# DA_IP_ADC_3v16bSAR_NN_C90LP: IP-XACT component
VLNV Origen:Origen:DA_IP_ADC_3v16bSAR_NN_C90LP:1.7

## Address spaces and blocks
.: base 0x0, range 124, width 32

## Registers
Registers are 32-bit, read-write, reset 0x0 unless marked. A register's access mark holds for its fields unless they carry their own. Offsets are from the block's base; lines under a group give offsets from that group; [hi:lo] are bit positions; {n}, {i} and the like mark numbered series; 'fields as' and 'values as' point back to an identical list; <NAME> marks a mode.

## block0
Base 0x00000000
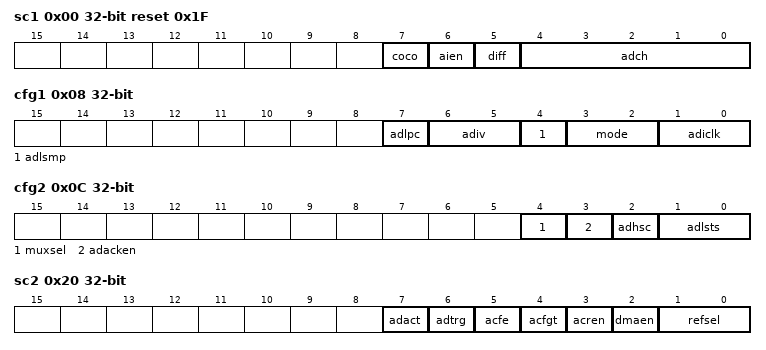
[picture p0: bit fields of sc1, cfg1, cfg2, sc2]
0x00 sc1 reset 0x1F — ADC Status and Control Registers 1
  [7] coco ro — Conversion Complete Flag
    0=Conversion is not completed; 1=Conversion is completed
  [6] aien — Interrupt Enable
    0=Conversion complete interrupt is disabled; 1=Conversion complete interrupt is enabled
  [5] diff — Differential Mode Enable
    0=Single-ended conversions and input channels are selected; 1=Differential conversions and input channels are selected
  [4:0] adch — Input channel select
    0=When DIFF=0, DADP0 is selected as input; when DIFF=1, DAD0 is selected as input. AD0 is selected as input.; 1=When DIFF=0, DADP1 is selected as input; when DIFF=1, DAD1 is selected as input. AD1 is selected as input.; 10=When DIFF=0, DADP2 is selected as input; when DIFF=1, DAD2 is selected as input. AD2 is selected as input.; 11=When DIFF=0, DADP3 is selected as input; when DIFF=1, DAD3 is selected as input. AD3 is selected as input.; 100=When DIFF=0, AD4 is selected as input; when DIFF=1, it is reserved; 101=When DIFF=0, AD5 is selected as input; when DIFF=1, it is reserved; 110=When DIFF=0, AD6 is selected as input; when DIFF=1, it is reserved; 111=When DIFF=0, AD7 is selected as input; when DIFF=1, it is reserved; 0x3E8=When DIFF=0, AD8 is selected as input; when DIFF=1, it is reserved; 0x3E9=When DIFF=0, AD9 is selected as input; when DIFF=1, it is reserved; 0x3F2=When DIFF=0, AD10 is selected as input; when DIFF=1, it is reserved; 0x3F3=When DIFF=0, AD11 is selected as input; when DIFF=1, it is reserved; 0x44C=When DIFF=0, AD12 is selected as input; when DIFF=1, it is reserved; 0x44D=When DIFF=0, AD13 is selected as input; when DIFF=1, it is reserved; 0x456=When DIFF=0, AD14 is selected as input; when DIFF=1, it is reserved; 0x457=When DIFF=0, AD15 is selected as input; when DIFF=1, it is reserved; 0x2710=When DIFF=0, AD16 is selected as input; when DIFF=1, it is reserved; 0x2711=When DIFF=0, AD17 is selected as input; when DIFF=1, it is reserved; 0x271A=When DIFF=0, AD18 is selected as input; when DIFF=1, it is reserved; 0x271B=When DIFF=0, AD19 is selected as input; when DIFF=1, it is reserved; 0x2774=When DIFF=0, AD20 is selected as input; when DIFF=1, it is reserved; 0x2775=When DIFF=0, AD21 is selected as input; when DIFF=1, it is reserved; 0x277E=When DIFF=0, AD22 is selected as input; when DIFF=1, it is reserved; 0x277F=When DIFF=0, AD23 is selected as input; when DIFF=1, it is reserved; 0x2B02=When DIFF=0, Temp Sensor (single-ended) is selected as input; when DIFF=1, Temp Sensor (differential) is selected as input; 0x2B03=When DIFF=0, Bandgap VREF\_OUT (single-ended) is selected as input; when DIFF=1, Bandgap VREF\_OUT (differential) is selected as input; 0x2B5D=When DIFF=0,VREFSH is selected as input; when DIFF=1, -VREFSH (differential) is selected as input. Voltage reference selected is determined by SC2\[REFSEL\].; 0x2B66=When DIFF=0,VREFSL is selected as input; when DIFF=1, it is reserved. Voltage reference selected is determined by SC2\[REFSEL\].; 0x2B67=Module is disabled
0x08 cfg1 — ADC Configuration Register 1
  [7] adlpc — Low-Power Configuration
    0=Normal power configuration; 1=Low-power configuration. The power is reduced at the expense of maximum clock speed.
  [6:5] adiv — Clock Divide Select
    0=The divide ratio is 1 and the clock rate is input clock; 1=The divide ratio is 2 and the clock rate is (input clock)/2; 10=The divide ratio is 4 and the clock rate is (input clock)/4; 11=The divide ratio is 8 and the clock rate is (input clock)/8
  [4] adlsmp — Sample Time Configuration
    0=Short sample time; 1=Long sample time
  [3:2] mode — Conversion mode selection
    0=When DIFF=0:It is single-ended 8-bit conversion; when DIFF=1, it is differential 9-bit conversion with 2\'s complement output; 1=When DIFF=0:It is single-ended 12-bit conversion ; when DIFF=1, it is differential 13-bit conversion with 2\'s complement output; 10=When DIFF=0:It is single-ended 10-bit conversion. ; when DIFF=1, it is differential 11-bit conversion with 2\'s complement output; 11=When DIFF=0:It is single-ended 16-bit conversion..; when DIFF=1, it is differential 16-bit conversion with 2\'s complement output Reserved. Do not set the field to this value.
  [1:0] adiclk — Input Clock Select
    0=Bus clock; 1=Alternate clock 2 (ALTCLK2) Bus clock divided by 2(BUSCLK/2); 10=Alternate clock (ALTCLK); 11=Asynchronous clock (ADACK)
0x0C cfg2 — ADC Configuration Register 2
  [4] muxsel — ADC Mux Select
    0=ADxxa channels are selected; 1=ADxxb channels are selected
  [3] adacken — Asynchronous Clock Output Enable
    0=Asynchronous clock output disabled; Asynchronous clock is enabled only if selected by ADICLK and a conversion is active; 1=Asynchronous clock and clock output is enabled regardless of the state of the ADC
  [2] adhsc — High-Speed Configuration
    0=Normal conversion sequence selected; 1=High-speed conversion sequence selected with 2 additional ADCK cycles to total conversion time
  [1:0] adlsts — Long Sample Time Select
    0=Default longest sample time; 20 extra ADCK cycles; 24 ADCK cycles total; 1=12 extra ADCK cycles; 16 ADCK cycles total sample time; 10=6 extra ADCK cycles; 10 ADCK cycles total sample time; 11=2 extra ADCK cycles; 6 ADCK cycles total sample time
0x10 r ro — ADC Data Result Register
  [15:0] d — Data result
0x18 cv — Compare Value Registers
  [15:0] cv — Compare Value.
0x20 sc2 — Status and Control Register 2
  [7] adact ro — Conversion Active
    0=Conversion not in progress; 1=Conversion in progress
  [6] adtrg — Conversion Trigger Select
    0=Software trigger selected; 1=Hardware trigger selected
  [5] acfe — Compare Function Enable
    0=Compare function disabled; 1=Compare function enabled
  [4] acfgt — Compare Function Greater Than Enable
    0=Configures less than threshold, outside range not inclusive and inside range not inclusive; functionality based on the values placed in CV1 and CV2; 1=Configures greater than or equal to threshold, outside and inside ranges inclusive; functionality based on the values placed in CV1 and CV2
  [3] acren — Compare Function Range Enable
    0=Range function disabled. Only CV1 is compared. \{27}; 1=Range function enabled. Both CV1 and CV2 are compared. \{27}
  [2] dmaen — DMA Enable
    0=DMA is disabled; 1=DMA is enabled and will assert the ADC DMA request during an ADC conversion complete event noted when any of the SC1n\[COCO\] flags is asserted
  [1:0] refsel — Voltage Reference Selection
    0=Default voltage reference pin pair, that is, external pins VREFH and VREFL; 1=Alternate reference pair, that is, VALTH and VALTL . This pair may be additional external pins or internal sources depending on the MCU configuration. See the chip configuration information for details specific to this MCU; 10=Internal bandgap reference and associated ground reference (V BGH and V BGL ). Consult the Chip Configuration information for details specific to this MCU. Reserved; 11=Reserved - Selects default voltage reference (V REFH and V REFL ) pin pair
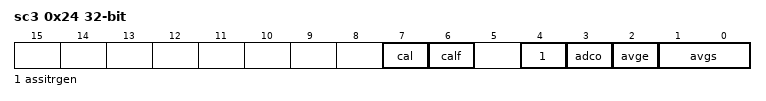
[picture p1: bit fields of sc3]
0x24 sc3 — Status and Control Register 3
  [7] cal — Calibration
  [6] calf — Calibration Failed Flag
    0=Calibration completed normally; 1=Calibration failed. ADC accuracy specifications are not guaranteed.
  [4] assitrgen — Assist Trigger Enable
    0=Writes to ADCSC1 COCO bit don\'t have an affect on ADTRG; 1=Writes to ADCSC1 COCO bit will be reflected into ADTRG register. Note: When ASSITRGEN is set, writes to ADCSC1 are delayed by 1/2 bus cycle to allow ADCSC1 COCO write to be updated in ADTRG register so conversion type can be correctly generated (software if coco write is 1\'b0 causing ADTRG to clear or hardware type if coco write is 1\'b1.). Note: User must ensure no hardware trigger is generated between the time ADCSC1 COCO bit is written if value of ADTRG will change to guarantee correct conversion type is generated.
  [3] adco — Continuous Conversion Enable
    0=One conversion or one set of conversions if the hardware average function is enabled, that is, AVGE=1, after initiating a conversion; 1=Continuous conversions or sets of conversions if the hardware average function is enabled, that is, AVGE=1, after initiating a conversion
  [2] avge — Hardware Average Enable
    0=Hardware average function disabled; 1=Hardware average function enabled
  [1:0] avgs — Hardware Average Select
    0=4 samples averaged; 1=8 samples averaged; 10=16 samples averaged; 11=32 samples averaged
0x28 ofs reset 0x4 — ADC Offset Correction Register
  [15:0] ofs — Offset Error Correction Value
0x2C pg reset 0x8200 — ADC Plus-Side Gain Register
  [15:0] pg — Plus-Side Gain
0x30 mg reset 0x8200 — ADC Minus-Side Gain Register
  [15:0] mg — Minus-Side Gain
0x34 clpd reset 0xA — ADC Plus-Side General Calibration Value Register
  [5:0] clpd — Calibration Value
0x38 clps reset 0x20 — ADC Plus-Side General Calibration Value Register
  [5:0] clps — Calibration Value
0x3C clp4 reset 0x200 — ADC Plus-Side General Calibration Value Register
  [9:0] clp4 — Calibration Value
0x40 clp3 reset 0x100 — ADC Plus-Side General Calibration Value Register
  [8:0] clp3 — Calibration Value
0x44 clp2 reset 0x80 — ADC Plus-Side General Calibration Value Register
  [7:0] clp2 — Calibration Value
0x48 clp1 reset 0x40 — ADC Plus-Side General Calibration Value Register
  [6:0] clp1 — Calibration Value
0x4C clp0 reset 0x20 — ADC Plus-Side General Calibration Value Register
  [5:0] clp0 — Calibration Value
0x54 clmd reset 0xA — ADC Minus-Side General Calibration Value Register
  [5:0] clmd — Calibration Value
0x58 clms reset 0x20 — ADC Minus-Side General Calibration Value Register
  [5:0] clms — Calibration Value
0x5C clm4 reset 0x200 — ADC Minus-Side General Calibration Value Register
  [9:0] clm4 — Calibration Value
0x60 clm3 reset 0x100 — ADC Minus-Side General Calibration Value Register
  [8:0] clm3 — Calibration Value
0x64 clm2 reset 0x80 — ADC Minus-Side General Calibration Value Register
  [7:0] clm2 — Calibration Value
0x68 clm1 reset 0x40 — ADC Minus-Side General Calibration Value Register
  [6:0] clm1 — Calibration Value
0x6C clm0 reset 0x20 — ADC Minus-Side General Calibration Value Register
  [5:0] clm0 — Calibration Value
